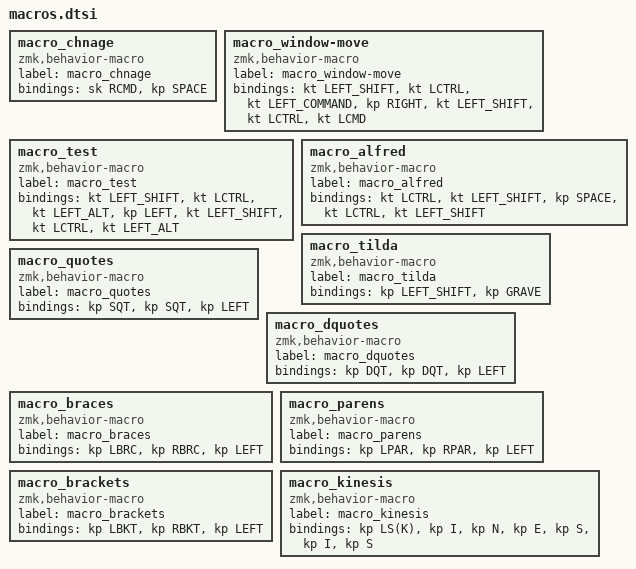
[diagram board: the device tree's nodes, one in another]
macro_chnage: macro_chnage{
compatible = "zmk,behavior-macro";
label = "macro_chnage";
#binding-cells = <0>;
bindings = <&sk RCMD>, <&kp SPACE>;
};
macro_window-move: macro_window-move{
compatible = "zmk,behavior-macro";
label = "macro_window-move";
#binding-cells = <0>;
bindings = <&kt LEFT_SHIFT>, <&kt LCTRL>, <&kt LEFT_COMMAND>, <&kp RIGHT>, <&kt LEFT_SHIFT>, <&kt LCTRL>, <&kt LCMD>;
};
macro_test: macro_test{
compatible = "zmk,behavior-macro";
label = "macro_test";
#binding-cells = <0>;
bindings = <&kt LEFT_SHIFT>, <&kt LCTRL>, <&kt LEFT_ALT>, <&kp LEFT>, <&kt LEFT_SHIFT>, <&kt LCTRL>, <&kt LEFT_ALT>;
};
macro_alfred: macro_alfred{
compatible = "zmk,behavior-macro";
label = "macro_alfred";
#binding-cells = <0>;
bindings = <&kt LCTRL>, <&kt LEFT_SHIFT>, <&kp SPACE>, <&kt LCTRL>, <&kt LEFT_SHIFT>;
};
macro_tilda: macro_tilda{
compatible = "zmk,behavior-macro";
label = "macro_tilda";
#binding-cells = <0>;
bindings = <&kp LEFT_SHIFT>, <&kp GRAVE>;
};
macro_quotes: macro_quotes{
compatible = "zmk,behavior-macro";
label = "macro_quotes";
#binding-cells = <0>;
bindings = <&kp SQT>, <&kp SQT>, <&kp LEFT>;
};
macro_dquotes: macro_dquotes{
compatible = "zmk,behavior-macro";
label = "macro_dquotes";
#binding-cells = <0>;
bindings = <&kp DQT>, <&kp DQT>, <&kp LEFT>;
};
macro_braces: macro_braces{
compatible = "zmk,behavior-macro";
label = "macro_braces";
#binding-cells = <0>;
bindings = <&kp LBRC>, <&kp RBRC>, <&kp LEFT>;
};
macro_parens: macro_parens{
compatible = "zmk,behavior-macro";
label = "macro_parens";
#binding-cells = <0>;
bindings = <&kp LPAR>, <&kp RPAR>, <&kp LEFT>;
};
macro_brackets: macro_brackets{
compatible = "zmk,behavior-macro";
label = "macro_brackets";
#binding-cells = <0>;
bindings = <&kp LBKT>, <&kp RBKT>, <&kp LEFT>;
};
macro_kinesis: macro_kinesis{
compatible = "zmk,behavior-macro";
label = "macro_kinesis";
#binding-cells = <0>;
bindings = <&kp LS(K)>, <&kp I>, <&kp N>, <&kp E>, <&kp S>, <&kp I>, <&kp S>;
};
